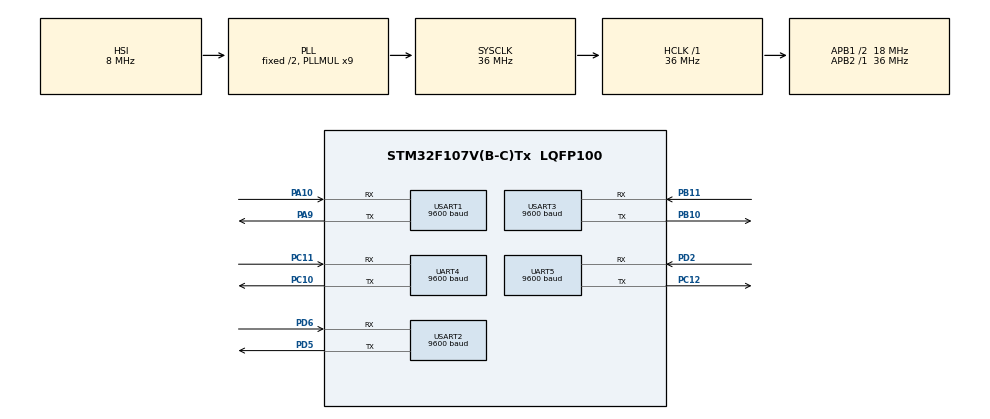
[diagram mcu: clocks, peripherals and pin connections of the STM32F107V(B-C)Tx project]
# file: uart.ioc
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FREERTOS.BinarySemaphores01=UART1_txCplt_BinarySem,Dynamic,NULL;UART1_rxCplt_BinarySem,Dynamic,NULL;UART2_txCplt_BinarySem,Dynamic,NULL;UART2_rxCplt_BinarySem,Dynamic,NULL;UART3_txCplt_BinarySem,Dynamic,NULL;UART3_rxCplt_BinarySem,Dynamic,NULL;UART4_txCplt_BinarySem,Dynamic,NULL;UART4_rxCplt_BinarySem,Dynamic,NULL;UART5_txCplt_BinarySem,Dynamic,NULL;UART5_rxCplt_BinarySem,Dynamic,NULL
FREERTOS.Tasks01=defaultTask,24,256,StartDefaultTask,Default,NULL,Dynamic,NULL,NULL;myTask02,24,256,StartTask02,Default,NULL,Dynamic,NULL,NULL
Mcu.Family=STM32F1
Mcu.Name=STM32F107V(B-C)Tx
Mcu.Package=LQFP100
NVIC.PriorityGroup=NVIC_PRIORITYGROUP_4
NVIC.TIM1_UP_IRQn=true\:0\:0\:false\:false\:true\:false\:false\:true
NVIC.TimeBase=TIM1_UP_IRQn
NVIC.TimeBaseIP=TIM1
NVIC.UART4_IRQn=true\:5\:0\:false\:false\:true\:true\:true\:true
NVIC.UART5_IRQn=true\:5\:0\:false\:false\:true\:true\:true\:true
NVIC.USART1_IRQn=true\:5\:0\:false\:false\:true\:true\:true\:true
NVIC.USART2_IRQn=true\:5\:0\:false\:false\:true\:true\:true\:true
NVIC.USART3_IRQn=true\:5\:0\:false\:false\:true\:true\:true\:true
OSC_IN.Mode=HSE-External-Oscillator
OSC_IN.Signal=RCC_OSC_IN
OSC_OUT.Mode=HSE-External-Oscillator
OSC_OUT.Signal=RCC_OSC_OUT
PA10.GPIO_PuPd=GPIO_PULLUP
PA10.Mode=Asynchronous
PA10.Signal=USART1_RX
PA13.Mode=Serial_Wire
PA13.Signal=SYS_JTMS-SWDIO
PA14.Mode=Serial_Wire
PA14.Signal=SYS_JTCK-SWCLK
PA9.Mode=Asynchronous
PA9.Signal=USART1_TX
PB10.Mode=Asynchronous
PB10.Signal=USART3_TX
PB11.GPIO_PuPd=GPIO_PULLUP
PB11.Mode=Asynchronous
PB11.Signal=USART3_RX
PC10.Mode=Asynchronous
PC10.Signal=UART4_TX
PC11.GPIO_PuPd=GPIO_PULLUP
PC11.Mode=Asynchronous
PC11.Signal=UART4_RX
PC12.Mode=Asynchronous
PC12.Signal=UART5_TX
PC14-OSC32_IN.Mode=LSE-External-Oscillator
PC14-OSC32_IN.Signal=RCC_OSC32_IN
PC15-OSC32_OUT.Mode=LSE-External-Oscillator
PC15-OSC32_OUT.Signal=RCC_OSC32_OUT
PD2.GPIO_PuPd=GPIO_PULLUP
PD2.Mode=Asynchronous
PD2.Signal=UART5_RX
PD5.Mode=Asynchronous
PD5.Signal=USART2_TX
PD6.GPIO_PuPd=GPIO_PULLUP
PD6.Mode=Asynchronous
PD6.Signal=USART2_RX
ProjectManager.HeapSize=0x200
ProjectManager.StackSize=0x400
ProjectManager.TargetToolchain=EWARM V8.32
RCC.AHBFreq_Value=36000000
RCC.APB1CLKDivider=RCC_HCLK_DIV2
RCC.APB1Freq_Value=18000000
RCC.APB1TimFreq_Value=36000000
RCC.APB2Freq_Value=36000000
RCC.APB2TimFreq_Value=36000000
RCC.HCLKFreq_Value=36000000
RCC.HSEDivPLL=RCC_HSE_PREDIV_DIV5
RCC.HSE_VALUE=25000000
RCC.PLLMUL=RCC_PLL_MUL9
RCC.Prediv1Source=RCC_PREDIV1_SOURCE_PLL2
RCC.Prediv2=RCC_HSE_PREDIV2_DIV5
RCC.SYSCLKFreq_VALUE=36000000
RCC.SYSCLKSource=RCC_SYSCLKSOURCE_PLLCLK
RCC.USBFreq_Value=24000000
UART4.BaudRate=9600
UART4.VirtualMode=Asynchronous
UART5.BaudRate=9600
UART5.VirtualMode=Asynchronous
USART1.BaudRate=9600
USART1.VirtualMode=VM_ASYNC
USART2.BaudRate=9600
USART2.VirtualMode=VM_ASYNC
USART3.BaudRate=9600
USART3.VirtualMode=VM_ASYNC
VP_CRC_VS_CRC.Mode=CRC_Activate
VP_FREERTOS_VS_CMSIS_V2.Mode=CMSIS_V2
VP_SYS_VS_tim1.Mode=TIM1
board=custom

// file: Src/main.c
/* USER CODE BEGIN Header */
/**
  ******************************************************************************
  * @file           : main.c
  * @brief          : Main program body
  ******************************************************************************
  * @attention
  *
  * <h2><center>&copy; Copyright (c) 2020 STMicroelectronics.
  * All rights reserved.</center></h2>
  *
  * This software component is licensed by ST under Ultimate Liberty license
  * SLA0044, the "License"; You may not use this file except in compliance with
  * the License. You may obtain a copy of the License at:
  *                             www.st.com/SLA0044
  *
  ******************************************************************************
  */
/* USER CODE END Header */

#include "main.h"
#include "cmsis_os.h"

/* USER CODE BEGIN Includes */
#include "AppTask.h"
/* USER CODE END Includes */

CRC_HandleTypeDef hcrc;

UART_HandleTypeDef huart4;
UART_HandleTypeDef huart5;
UART_HandleTypeDef huart1;
UART_HandleTypeDef huart2;
UART_HandleTypeDef huart3;

osThreadId_t defaultTaskHandle;
osThreadId_t myTask02Handle;
osSemaphoreId_t UART1_txCplt_BinarySemHandle;
osSemaphoreId_t UART1_rxCplt_BinarySemHandle;
osSemaphoreId_t UART2_txCplt_BinarySemHandle;
osSemaphoreId_t UART2_rxCplt_BinarySemHandle;
osSemaphoreId_t UART3_txCplt_BinarySemHandle;
osSemaphoreId_t UART3_rxCplt_BinarySemHandle;
osSemaphoreId_t UART4_txCplt_BinarySemHandle;
osSemaphoreId_t UART4_rxCplt_BinarySemHandle;
osSemaphoreId_t UART5_txCplt_BinarySemHandle;
osSemaphoreId_t UART5_rxCplt_BinarySemHandle;

void SystemClock_Config(void);
static void MX_GPIO_Init(void);
static void MX_CRC_Init(void);
static void MX_USART1_UART_Init(void);
static void MX_USART2_UART_Init(void);
static void MX_USART3_UART_Init(void);
static void MX_UART4_Init(void);
static void MX_UART5_Init(void);
void StartDefaultTask(void *argument);
void StartTask02(void *argument);

int main(void)
{

  /* MCU Configuration--------------------------------------------------------*/

  /* Reset of all peripherals, Initializes the Flash interface and the Systick. */
  HAL_Init();

  /* Configure the system clock */
  SystemClock_Config();

  /* Initialize all configured peripherals */
  MX_GPIO_Init();
  MX_CRC_Init();
  MX_USART1_UART_Init();
  MX_USART2_UART_Init();
  MX_USART3_UART_Init();
  MX_UART4_Init();
  MX_UART5_Init();

  osKernelInitialize();

  /* Create the semaphores(s) */
  /* definition and creation of UART1_txCplt_BinarySem */
  const osSemaphoreAttr_t UART1_txCplt_BinarySem_attributes = {
    .name = "UART1_txCplt_BinarySem"
  };
  UART1_txCplt_BinarySemHandle = osSemaphoreNew(1, 1, &UART1_txCplt_BinarySem_attributes);

  /* definition and creation of UART1_rxCplt_BinarySem */
  const osSemaphoreAttr_t UART1_rxCplt_BinarySem_attributes = {
    .name = "UART1_rxCplt_BinarySem"
  };
  UART1_rxCplt_BinarySemHandle = osSemaphoreNew(1, 1, &UART1_rxCplt_BinarySem_attributes);

  /* definition and creation of UART2_txCplt_BinarySem */
  const osSemaphoreAttr_t UART2_txCplt_BinarySem_attributes = {
    .name = "UART2_txCplt_BinarySem"
  };
  UART2_txCplt_BinarySemHandle = osSemaphoreNew(1, 1, &UART2_txCplt_BinarySem_attributes);

  /* definition and creation of UART2_rxCplt_BinarySem */
  const osSemaphoreAttr_t UART2_rxCplt_BinarySem_attributes = {
    .name = "UART2_rxCplt_BinarySem"
  };
  UART2_rxCplt_BinarySemHandle = osSemaphoreNew(1, 1, &UART2_rxCplt_BinarySem_attributes);

  /* definition and creation of UART3_txCplt_BinarySem */
  const osSemaphoreAttr_t UART3_txCplt_BinarySem_attributes = {
    .name = "UART3_txCplt_BinarySem"
  };
  UART3_txCplt_BinarySemHandle = osSemaphoreNew(1, 1, &UART3_txCplt_BinarySem_attributes);

  /* definition and creation of UART3_rxCplt_BinarySem */
  const osSemaphoreAttr_t UART3_rxCplt_BinarySem_attributes = {
    .name = "UART3_rxCplt_BinarySem"
  };
  UART3_rxCplt_BinarySemHandle = osSemaphoreNew(1, 1, &UART3_rxCplt_BinarySem_attributes);

  /* definition and creation of UART4_txCplt_BinarySem */
  const osSemaphoreAttr_t UART4_txCplt_BinarySem_attributes = {
    .name = "UART4_txCplt_BinarySem"
  };
  UART4_txCplt_BinarySemHandle = osSemaphoreNew(1, 1, &UART4_txCplt_BinarySem_attributes);

  /* definition and creation of UART4_rxCplt_BinarySem */
  const osSemaphoreAttr_t UART4_rxCplt_BinarySem_attributes = {
    .name = "UART4_rxCplt_BinarySem"
  };
  UART4_rxCplt_BinarySemHandle = osSemaphoreNew(1, 1, &UART4_rxCplt_BinarySem_attributes);

  /* definition and creation of UART5_txCplt_BinarySem */
  const osSemaphoreAttr_t UART5_txCplt_BinarySem_attributes = {
    .name = "UART5_txCplt_BinarySem"
  };
  UART5_txCplt_BinarySemHandle = osSemaphoreNew(1, 1, &UART5_txCplt_BinarySem_attributes);

  /* definition and creation of UART5_rxCplt_BinarySem */
  const osSemaphoreAttr_t UART5_rxCplt_BinarySem_attributes = {
    .name = "UART5_rxCplt_BinarySem"
  };
  UART5_rxCplt_BinarySemHandle = osSemaphoreNew(1, 1, &UART5_rxCplt_BinarySem_attributes);

  /* Create the thread(s) */
  /* definition and creation of defaultTask */
  const osThreadAttr_t defaultTask_attributes = {
    .name = "defaultTask",
    .priority = (osPriority_t) osPriorityNormal,
    .stack_size = 256
  };
  defaultTaskHandle = osThreadNew(StartDefaultTask, NULL, &defaultTask_attributes);

  /* definition and creation of myTask02 */
  const osThreadAttr_t myTask02_attributes = {
    .name = "myTask02",
    .priority = (osPriority_t) osPriorityNormal,
    .stack_size = 256
  };
  myTask02Handle = osThreadNew(StartTask02, NULL, &myTask02_attributes);

  /* Start scheduler */
  osKernelStart();

  /* We should never get here as control is now taken by the scheduler */

  /* Infinite loop */
  while (1)
  {

  }
}

void SystemClock_Config(void)
{
  RCC_OscInitTypeDef RCC_OscInitStruct = {0};
  RCC_ClkInitTypeDef RCC_ClkInitStruct = {0};

  /** Initializes the CPU, AHB and APB busses clocks
  */
  RCC_OscInitStruct.OscillatorType = RCC_OSCILLATORTYPE_HSI;
  RCC_OscInitStruct.HSIState = RCC_HSI_ON;
  RCC_OscInitStruct.HSICalibrationValue = RCC_HSICALIBRATION_DEFAULT;
  RCC_OscInitStruct.Prediv1Source = RCC_PREDIV1_SOURCE_PLL2;
  RCC_OscInitStruct.PLL.PLLState = RCC_PLL_ON;
  RCC_OscInitStruct.PLL.PLLSource = RCC_PLLSOURCE_HSI_DIV2;
  RCC_OscInitStruct.PLL.PLLMUL = RCC_PLL_MUL9;
  RCC_OscInitStruct.PLL2.PLL2State = RCC_PLL_NONE;
  if (HAL_RCC_OscConfig(&RCC_OscInitStruct) != HAL_OK)
  {
    Error_Handler();
  }
  /** Initializes the CPU, AHB and APB busses clocks
  */
  RCC_ClkInitStruct.ClockType = RCC_CLOCKTYPE_HCLK|RCC_CLOCKTYPE_SYSCLK
                              |RCC_CLOCKTYPE_PCLK1|RCC_CLOCKTYPE_PCLK2;
  RCC_ClkInitStruct.SYSCLKSource = RCC_SYSCLKSOURCE_PLLCLK;
  RCC_ClkInitStruct.AHBCLKDivider = RCC_SYSCLK_DIV1;
  RCC_ClkInitStruct.APB1CLKDivider = RCC_HCLK_DIV2;
  RCC_ClkInitStruct.APB2CLKDivider = RCC_HCLK_DIV1;

  if (HAL_RCC_ClockConfig(&RCC_ClkInitStruct, FLASH_LATENCY_1) != HAL_OK)
  {
    Error_Handler();
  }
  /** Configure the Systick interrupt time
  */
  __HAL_RCC_PLLI2S_ENABLE();
}

static void MX_CRC_Init(void)
{

  hcrc.Instance = CRC;
  if (HAL_CRC_Init(&hcrc) != HAL_OK)
  {
    Error_Handler();
  }

}

static void MX_UART4_Init(void)
{

  huart4.Instance = UART4;
  huart4.Init.BaudRate = 9600;
  huart4.Init.WordLength = UART_WORDLENGTH_8B;
  huart4.Init.StopBits = UART_STOPBITS_1;
  huart4.Init.Parity = UART_PARITY_NONE;
  huart4.Init.Mode = UART_MODE_TX_RX;
  huart4.Init.HwFlowCtl = UART_HWCONTROL_NONE;
  huart4.Init.OverSampling = UART_OVERSAMPLING_16;
  if (HAL_UART_Init(&huart4) != HAL_OK)
  {
    Error_Handler();
  }

}

static void MX_UART5_Init(void)
{

  huart5.Instance = UART5;
  huart5.Init.BaudRate = 9600;
  huart5.Init.WordLength = UART_WORDLENGTH_8B;
  huart5.Init.StopBits = UART_STOPBITS_1;
  huart5.Init.Parity = UART_PARITY_NONE;
  huart5.Init.Mode = UART_MODE_TX_RX;
  huart5.Init.HwFlowCtl = UART_HWCONTROL_NONE;
  huart5.Init.OverSampling = UART_OVERSAMPLING_16;
  if (HAL_UART_Init(&huart5) != HAL_OK)
  {
    Error_Handler();
  }

}

static void MX_USART1_UART_Init(void)
{

  huart1.Instance = USART1;
  huart1.Init.BaudRate = 9600;
  huart1.Init.WordLength = UART_WORDLENGTH_8B;
  huart1.Init.StopBits = UART_STOPBITS_1;
  huart1.Init.Parity = UART_PARITY_NONE;
  huart1.Init.Mode = UART_MODE_TX_RX;
  huart1.Init.HwFlowCtl = UART_HWCONTROL_NONE;
  huart1.Init.OverSampling = UART_OVERSAMPLING_16;
  if (HAL_UART_Init(&huart1) != HAL_OK)
  {
    Error_Handler();
  }

}

static void MX_USART2_UART_Init(void)
{

  huart2.Instance = USART2;
  huart2.Init.BaudRate = 9600;
  huart2.Init.WordLength = UART_WORDLENGTH_8B;
  huart2.Init.StopBits = UART_STOPBITS_1;
  huart2.Init.Parity = UART_PARITY_NONE;
  huart2.Init.Mode = UART_MODE_TX_RX;
  huart2.Init.HwFlowCtl = UART_HWCONTROL_NONE;
  huart2.Init.OverSampling = UART_OVERSAMPLING_16;
  if (HAL_UART_Init(&huart2) != HAL_OK)
  {
    Error_Handler();
  }

}

static void MX_USART3_UART_Init(void)
{

  huart3.Instance = USART3;
  huart3.Init.BaudRate = 9600;
  huart3.Init.WordLength = UART_WORDLENGTH_8B;
  huart3.Init.StopBits = UART_STOPBITS_1;
  huart3.Init.Parity = UART_PARITY_NONE;
  huart3.Init.Mode = UART_MODE_TX_RX;
  huart3.Init.HwFlowCtl = UART_HWCONTROL_NONE;
  huart3.Init.OverSampling = UART_OVERSAMPLING_16;
  if (HAL_UART_Init(&huart3) != HAL_OK)
  {
    Error_Handler();
  }

}

static void MX_GPIO_Init(void)
{

  /* GPIO Ports Clock Enable */
  __HAL_RCC_GPIOC_CLK_ENABLE();
  __HAL_RCC_GPIOB_CLK_ENABLE();
  __HAL_RCC_GPIOA_CLK_ENABLE();
  __HAL_RCC_GPIOD_CLK_ENABLE();

}

void StartDefaultTask(void *argument)
{
  /* USER CODE BEGIN 5 */
  /* Infinite loop */
    default_task();
//  for(;;)
//  {
//    osDelay(1);
//  }
  /* USER CODE END 5 */
}

void StartTask02(void *argument)
{
  /* USER CODE BEGIN StartTask02 */
  /* Infinite loop */
    my_task();
//  for(;;)
//  {
//    osDelay(1);
//  }
  /* USER CODE END StartTask02 */
}

void HAL_TIM_PeriodElapsedCallback(TIM_HandleTypeDef *htim)
{
  if (htim->Instance == TIM1) {
    HAL_IncTick();
  }
}

void Error_Handler(void)
{
}

/************************ (C) COPYRIGHT STMicroelectronics *****END OF FILE****/
